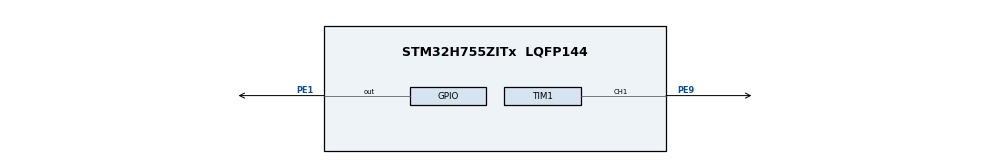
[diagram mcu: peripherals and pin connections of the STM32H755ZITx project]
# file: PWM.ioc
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CortexM4.IPs=BDMA,CORTEX_M4\:I,DEBUG,DMA,FATFS_M4\:I,FREERTOS_M4\:I,GPIO,IWDG2\:I,MDMA,NVIC2\:I,OPENAMP_M4\:I,PDM2PCM_M4\:I,PWR,RCC,RESMGR_UTILITY,SYS_M4\:I,USB_DEVICE_M4\:I,USB_HOST_M4\:I,VREFBUF,WWDG2\:I
CortexM7.IPs=BDMA\:I,CORTEX_M7\:I,DEBUG\:I,DMA\:I,FATFS_M7\:I,FREERTOS_M7\:I,GPIO\:I,IWDG1\:I,MDMA\:I,NVIC1\:I,OPENAMP_M7\:I,PDM2PCM_M7\:I,PWR\:I,RCC\:I,RESMGR_UTILITY\:I,SYS\:I,USB_DEVICE_M7\:I,USB_HOST_M7\:I,VREFBUF\:I,WWDG1\:I,TIM1\:I
CortexM7.Pins=PE1
Mcu.Family=STM32H7
Mcu.Name=STM32H755ZITx
Mcu.Package=LQFP144
NVIC1.PriorityGroup=NVIC_PRIORITYGROUP_4
NVIC1.TIM1_UP_IRQn=true\:0\:0\:false\:false\:true\:true\:true\:true
NVIC2.PriorityGroup=NVIC_PRIORITYGROUP_4
PE1.GPIO_PuPd=GPIO_PULLDOWN
PE1.GPIO_Speed=GPIO_SPEED_FREQ_HIGH
PE1.PinAttribute=CortexM7
PE1.PinState=GPIO_PIN_RESET
PE1.Signal=GPIO_Output
PE9.PinAttribute=CortexM7
PE9.Signal=S_TIM1_CH1
PH0-OSC_IN\ (PH0).Mode=HSE-External-Oscillator
PH0-OSC_IN\ (PH0).PinAttribute=Free
PH0-OSC_IN\ (PH0).Signal=RCC_OSC_IN
PH1-OSC_OUT\ (PH1).Mode=HSE-External-Oscillator
PH1-OSC_OUT\ (PH1).PinAttribute=Free
PH1-OSC_OUT\ (PH1).Signal=RCC_OSC_OUT
ProjectManager.HeapSize=M4-0x200,M7-0x200
ProjectManager.StackSize=M4-0x400,M7-0x400
ProjectManager.TargetToolchain=STM32CubeIDE
RCC.ADCFreq_Value=129000000
RCC.APB1Freq_Value=1000000
RCC.APB2Freq_Value=1000000
RCC.APB3Freq_Value=1000000
RCC.APB4Freq_Value=1000000
RCC.CortexFreq_Value=1000000
RCC.D1CPRE=RCC_SYSCLK_DIV64
RCC.HCLKFreq_Value=1000000
RCC.SYSCLKFreq_VALUE=64000000
RCC.USBFreq_Value=129000000
SH.S_TIM1_CH1.0=TIM1_CH1,PWM Generation1 CH1
SYS.userName=SYS_M7
TIM1.Channel-PWM\ Generation1\ CH1=TIM_CHANNEL_1
TIM1.Period=1000
TIM1.Prescaler=1000 -1 
VP_SYS_M4_VS_Systick.Mode=SysTick
board=custom

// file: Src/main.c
/* USER CODE BEGIN Header */
/**
  ******************************************************************************
  * @file           : main.c
  * @brief          : Main program body
  ******************************************************************************
  * @attention
  *
  * Copyright (c) 2024 STMicroelectronics.
  * All rights reserved.
  *
  * This software is licensed under terms that can be found in the LICENSE file
  * in the root directory of this software component.
  * If no LICENSE file comes with this software, it is provided AS-IS.
  *
  ******************************************************************************
  */
/* USER CODE END Header */
#include "main.h"
#include "tim.h"
#include "gpio.h"

/* USER CODE BEGIN PD */

#ifndef HSEM_ID_0
#define HSEM_ID_0 (0U) /* HW semaphore 0*/
#endif

/* USER CODE END PD */

void SystemClock_Config(void);
static void MPU_Config(void);

int main(void)
{
/* USER CODE BEGIN Boot_Mode_Sequence_0 */
  int32_t timeout;
/* USER CODE END Boot_Mode_Sequence_0 */

  /* MPU Configuration--------------------------------------------------------*/
  MPU_Config();

/* USER CODE BEGIN Boot_Mode_Sequence_1 */
  /* Wait until CPU2 boots and enters in stop mode or timeout*/
  timeout = 0xFFFF;
  while((__HAL_RCC_GET_FLAG(RCC_FLAG_D2CKRDY) != RESET) && (timeout-- > 0));
  if ( timeout < 0 )
  {
  Error_Handler();
  }
/* USER CODE END Boot_Mode_Sequence_1 */
  /* MCU Configuration--------------------------------------------------------*/

  /* Reset of all peripherals, Initializes the Flash interface and the Systick. */
  HAL_Init();

  /* Configure the system clock */
  SystemClock_Config();
/* USER CODE BEGIN Boot_Mode_Sequence_2 */
/* When system initialization is finished, Cortex-M7 will release Cortex-M4 by means of
HSEM notification */
/*HW semaphore Clock enable*/
__HAL_RCC_HSEM_CLK_ENABLE();
/*Take HSEM */
HAL_HSEM_FastTake(HSEM_ID_0);
/*Release HSEM in order to notify the CPU2(CM4)*/
HAL_HSEM_Release(HSEM_ID_0,0);
/* wait until CPU2 wakes up from stop mode */
timeout = 0xFFFF;
while((__HAL_RCC_GET_FLAG(RCC_FLAG_D2CKRDY) == RESET) && (timeout-- > 0));
if ( timeout < 0 )
{
Error_Handler();
}
/* USER CODE END Boot_Mode_Sequence_2 */

  /* Initialize all configured peripherals */
  MX_GPIO_Init();
  MX_TIM1_Init();
  /* USER CODE BEGIN 2 */
  HAL_TIM_Base_Start_IT(&htim1);
  /* USER CODE END 2 */

  /* Infinite loop */
  while (1)
  {

  }
}

void SystemClock_Config(void)
{
  RCC_OscInitTypeDef RCC_OscInitStruct = {0};
  RCC_ClkInitTypeDef RCC_ClkInitStruct = {0};

  /** Supply configuration update enable
  */
  HAL_PWREx_ConfigSupply(PWR_DIRECT_SMPS_SUPPLY);

  /** Configure the main internal regulator output voltage
  */
  __HAL_PWR_VOLTAGESCALING_CONFIG(PWR_REGULATOR_VOLTAGE_SCALE3);

  while(!__HAL_PWR_GET_FLAG(PWR_FLAG_VOSRDY)) {}

  /** Initializes the RCC Oscillators according to the specified parameters
  * in the RCC_OscInitTypeDef structure.
  */
  RCC_OscInitStruct.OscillatorType = RCC_OSCILLATORTYPE_HSI;
  RCC_OscInitStruct.HSIState = RCC_HSI_DIV1;
  RCC_OscInitStruct.HSICalibrationValue = RCC_HSICALIBRATION_DEFAULT;
  RCC_OscInitStruct.PLL.PLLState = RCC_PLL_NONE;
  if (HAL_RCC_OscConfig(&RCC_OscInitStruct) != HAL_OK)
  {
    Error_Handler();
  }

  /** Initializes the CPU, AHB and APB buses clocks
  */
  RCC_ClkInitStruct.ClockType = RCC_CLOCKTYPE_HCLK|RCC_CLOCKTYPE_SYSCLK
                              |RCC_CLOCKTYPE_PCLK1|RCC_CLOCKTYPE_PCLK2
                              |RCC_CLOCKTYPE_D3PCLK1|RCC_CLOCKTYPE_D1PCLK1;
  RCC_ClkInitStruct.SYSCLKSource = RCC_SYSCLKSOURCE_HSI;
  RCC_ClkInitStruct.SYSCLKDivider = RCC_SYSCLK_DIV64;
  RCC_ClkInitStruct.AHBCLKDivider = RCC_HCLK_DIV1;
  RCC_ClkInitStruct.APB3CLKDivider = RCC_APB3_DIV1;
  RCC_ClkInitStruct.APB1CLKDivider = RCC_APB1_DIV1;
  RCC_ClkInitStruct.APB2CLKDivider = RCC_APB2_DIV1;
  RCC_ClkInitStruct.APB4CLKDivider = RCC_APB4_DIV1;

  if (HAL_RCC_ClockConfig(&RCC_ClkInitStruct, FLASH_LATENCY_0) != HAL_OK)
  {
    Error_Handler();
  }
}

/* USER CODE BEGIN 4 */
void HAL_TIM_PeriodElapsedCallback (TIM_HandleTypeDef *htim){

	// Checks if the timer that triggered this callback function is indeed our timer (TIM1)
	if(htim == &htim1){
		HAL_GPIO_TogglePin(GPIOE,GPIO_PIN_1);
	}

}

/* USER CODE END 4 */

/* MPU Configuration */

void MPU_Config(void)
{
  MPU_Region_InitTypeDef MPU_InitStruct = {0};

  /* Disables the MPU */
  HAL_MPU_Disable();

  /** Initializes and configures the Region and the memory to be protected
  */
  MPU_InitStruct.Enable = MPU_REGION_ENABLE;
  MPU_InitStruct.Number = MPU_REGION_NUMBER0;
  MPU_InitStruct.BaseAddress = 0x0;
  MPU_InitStruct.Size = MPU_REGION_SIZE_4GB;
  MPU_InitStruct.SubRegionDisable = 0x87;
  MPU_InitStruct.TypeExtField = MPU_TEX_LEVEL0;
  MPU_InitStruct.AccessPermission = MPU_REGION_NO_ACCESS;
  MPU_InitStruct.DisableExec = MPU_INSTRUCTION_ACCESS_DISABLE;
  MPU_InitStruct.IsShareable = MPU_ACCESS_SHAREABLE;
  MPU_InitStruct.IsCacheable = MPU_ACCESS_NOT_CACHEABLE;
  MPU_InitStruct.IsBufferable = MPU_ACCESS_NOT_BUFFERABLE;

  HAL_MPU_ConfigRegion(&MPU_InitStruct);
  /* Enables the MPU */
  HAL_MPU_Enable(MPU_PRIVILEGED_DEFAULT);

}

void Error_Handler(void)
{
  __disable_irq();
  while (1)
  {
  }
}
